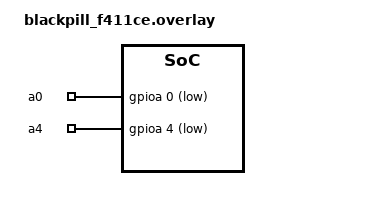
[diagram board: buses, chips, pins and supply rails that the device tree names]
/ {
    aliases {
        my-button-1 = &button_1;
        my-button-2 = &button_2;
    };

    custom-buttons {
        button_1: custom_button_1 {
            compatible = "custom,button";
            pin = <&a0>;
        };

        button_2: custom_button_2 {
            compatible = "custom,button";
            pin = <&a4>;
        };
    };

    gpio-keys-custom {
        compatible = "gpio-keys";

        a0: gpio0 {
            gpios = <&gpioa 0 (GPIO_ACTIVE_LOW | GPIO_PULL_UP)>;
        };

        a4: gpio1 {
            gpios = <&gpioa 4 (GPIO_ACTIVE_LOW | GPIO_PULL_UP)>;
        };
    };
};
